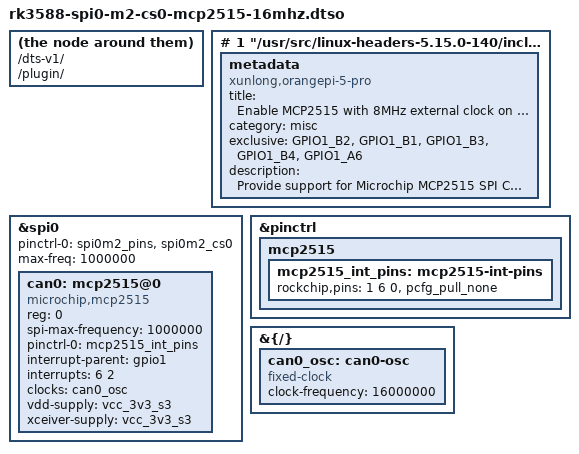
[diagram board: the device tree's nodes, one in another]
# 0 "rk3588-spi0-m2-cs0-mcp2515-16mhz.dts"
# 0 "<built-in>"
# 0 "<command-line>"
# 1 "rk3588-spi0-m2-cs0-mcp2515-16mhz.dts"
/dts-v1/;
/plugin/;

# 1 "/usr/src/linux-headers-5.15.0-140/include/dt-bindings/gpio/gpio.h" 1
# 5 "rk3588-spi0-m2-cs0-mcp2515-16mhz.dts" 2
# 1 "/usr/src/linux-headers-5.15.0-140/include/dt-bindings/pinctrl/rockchip.h" 1
# 6 "rk3588-spi0-m2-cs0-mcp2515-16mhz.dts" 2
# 1 "/usr/src/linux-headers-5.15.0-140/include/dt-bindings/interrupt-controller/irq.h" 1
# 7 "rk3588-spi0-m2-cs0-mcp2515-16mhz.dts" 2

/ {
    metadata {
        title = "Enable MCP2515 with 8MHz external clock on SPI0-M2 over CS0";

        compatible = "xunlong,orangepi-5-pro", "rockchip,rk3588";
        category = "misc";
        exclusive = "GPIO1_B2", "GPIO1_B1", "GPIO1_B3", "GPIO1_B4", "GPIO1_A6";
        description = "Provide support for Microchip MCP2515 SPI CAN controller.\nAssumes 16MHz external clock.\nUses Pin 31 (GPIO1_A6) for INT.";
    };
};

&spi0 {
    status = "okay";
    pinctrl-names = "default";
    pinctrl-0 = <&spi0m2_pins &spi0m2_cs0>;
    #address-cells = <1>;
    #size-cells = <0>;
    max-freq = <1000000>;

    can0: mcp2515@0 {
        status = "okay";
        compatible = "microchip,mcp2515";
        reg = <0>;
        spi-max-frequency = <1000000>;

        pinctrl-names = "default";
        pinctrl-0 = <&mcp2515_int_pins>;

        interrupt-parent = <&gpio1>;
        interrupts = <6 2>;

        clocks = <&can0_osc>;
        vdd-supply = <&vcc_3v3_s3>;
        xceiver-supply = <&vcc_3v3_s3>;
    };
};

&pinctrl {
    mcp2515 {
        mcp2515_int_pins: mcp2515-int-pins {
            rockchip,pins = <1 6 0 &pcfg_pull_none>;
        };
    };
};

&{/} {
    can0_osc: can0-osc {
        compatible = "fixed-clock";
        #clock-cells = <0>;
        clock-frequency = <16000000>;
    };
};
